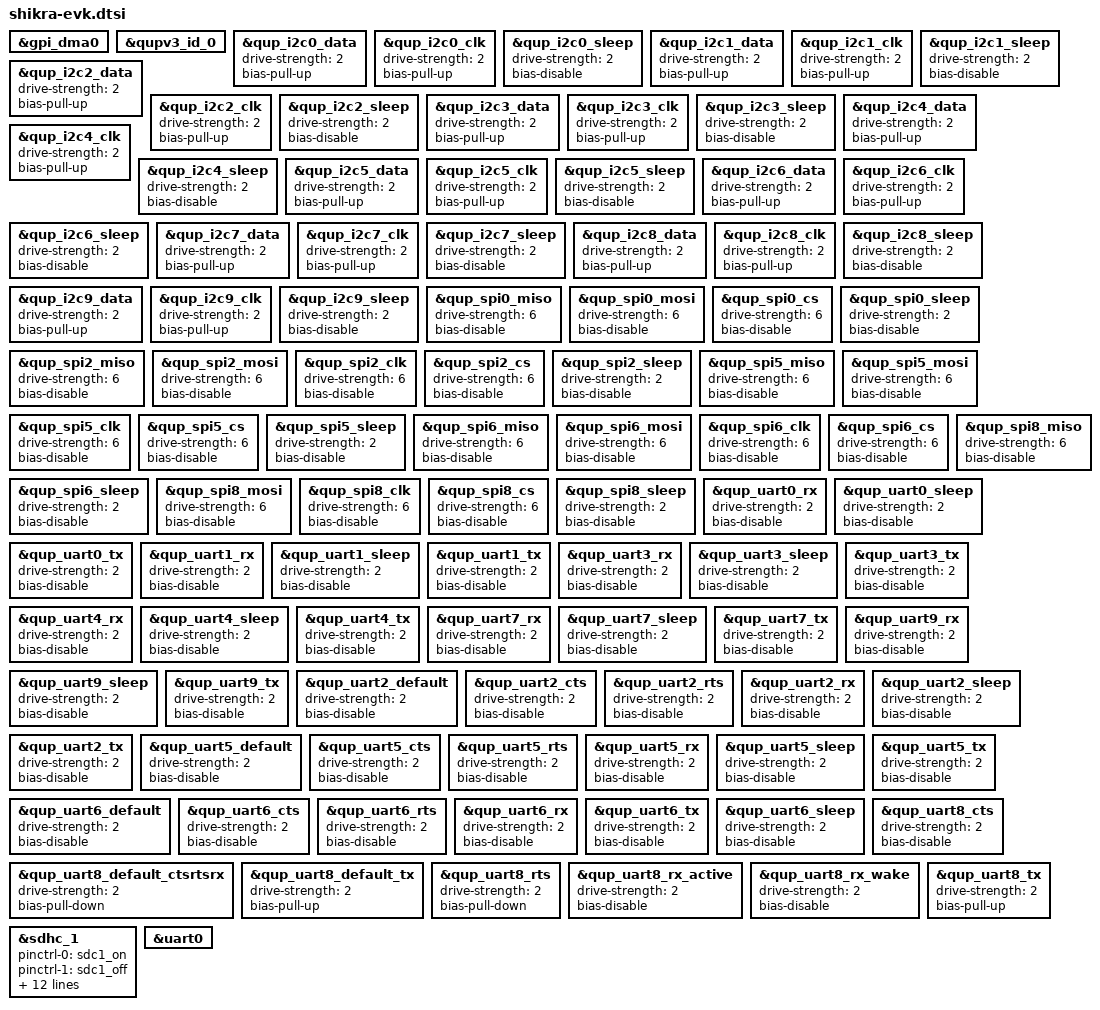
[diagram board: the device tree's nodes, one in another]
// SPDX-License-Identifier: BSD-3-Clause
/*
 * Copyright (c) Qualcomm Technologies, Inc. and/or its subsidiaries.
 */

&gpi_dma0 {
	status = "okay";
};

&qupv3_id_0 {
	status = "okay";
};

&qup_i2c0_data {
	drive-strength = <2>;
	bias-pull-up;
};

&qup_i2c0_clk {
	drive-strength = <2>;
	bias-pull-up;
};

&qup_i2c0_sleep {
	drive-strength = <2>;
	bias-disable;
};

&qup_i2c1_data {
	drive-strength = <2>;
	bias-pull-up;
};

&qup_i2c1_clk {
	drive-strength = <2>;
	bias-pull-up;
};

&qup_i2c1_sleep {
	drive-strength = <2>;
	bias-disable;
};

&qup_i2c2_data {
	drive-strength = <2>;
	bias-pull-up;
};

&qup_i2c2_clk {
	drive-strength = <2>;
	bias-pull-up;
};

&qup_i2c2_sleep {
	drive-strength = <2>;
	bias-disable;
};

&qup_i2c3_data {
	drive-strength = <2>;
	bias-pull-up;
};

&qup_i2c3_clk {
	drive-strength = <2>;
	bias-pull-up;
};

&qup_i2c3_sleep {
	drive-strength = <2>;
	bias-disable;
};

&qup_i2c4_data {
	drive-strength = <2>;
	bias-pull-up;
};

&qup_i2c4_clk {
	drive-strength = <2>;
	bias-pull-up;
};

&qup_i2c4_sleep {
	drive-strength = <2>;
	bias-disable;
};

&qup_i2c5_data {
	drive-strength = <2>;
	bias-pull-up;
};

&qup_i2c5_clk {
	drive-strength = <2>;
	bias-pull-up;
};

&qup_i2c5_sleep {
	drive-strength = <2>;
	bias-disable;
};

&qup_i2c6_data {
	drive-strength = <2>;
	bias-pull-up;
};

&qup_i2c6_clk {
	drive-strength = <2>;
	bias-pull-up;
};

&qup_i2c6_sleep {
	drive-strength = <2>;
	bias-disable;
};

&qup_i2c7_data {
	drive-strength = <2>;
	bias-pull-up;
};

&qup_i2c7_clk {
	drive-strength = <2>;
	bias-pull-up;
};

&qup_i2c7_sleep {
	drive-strength = <2>;
	bias-disable;
};

&qup_i2c8_data {
	drive-strength = <2>;
	bias-pull-up;
};

&qup_i2c8_clk {
	drive-strength = <2>;
	bias-pull-up;
};

&qup_i2c8_sleep {
	drive-strength = <2>;
	bias-disable;
};

&qup_i2c9_data {
	drive-strength = <2>;
	bias-pull-up;
};

&qup_i2c9_clk {
	drive-strength = <2>;
	bias-pull-up;
};

&qup_i2c9_sleep {
	drive-strength = <2>;
	bias-disable;
};

&qup_spi0_miso {
	drive-strength = <6>;
	bias-disable;
};

&qup_spi0_mosi {
	drive-strength = <6>;
	bias-disable;
};

&qup_spi0_cs {
	drive-strength = <6>;
	bias-disable;
};

&qup_spi0_sleep {
	drive-strength = <2>;
	bias-disable;
};

&qup_spi2_miso {
	drive-strength = <6>;
	bias-disable;
};

&qup_spi2_mosi {
	drive-strength = <6>;
	bias-disable;
};

&qup_spi2_clk {
	drive-strength = <6>;
	bias-disable;
};

&qup_spi2_cs {
	drive-strength = <6>;
	bias-disable;
};

&qup_spi2_sleep {
	drive-strength = <2>;
	bias-disable;
};

&qup_spi5_miso {
	drive-strength = <6>;
	bias-disable;
};

&qup_spi5_mosi {
	drive-strength = <6>;
	bias-disable;
};

&qup_spi5_clk {
	drive-strength = <6>;
	bias-disable;
};

&qup_spi5_cs {
	drive-strength = <6>;
	bias-disable;
};

&qup_spi5_sleep {
	drive-strength = <2>;
	bias-disable;
};

&qup_spi6_miso {
	drive-strength = <6>;
	bias-disable;
};

&qup_spi6_mosi {
	drive-strength = <6>;
	bias-disable;
};

&qup_spi6_clk {
	drive-strength = <6>;
	bias-disable;
};

&qup_spi6_cs {
	drive-strength = <6>;
	bias-disable;
};

&qup_spi6_sleep {
	drive-strength = <2>;
	bias-disable;
};

&qup_spi8_miso {
	drive-strength = <6>;
	bias-disable;
};

&qup_spi8_mosi {
	drive-strength = <6>;
	bias-disable;
};

&qup_spi8_clk {
	drive-strength = <6>;
	bias-disable;
};

&qup_spi8_cs {
	drive-strength = <6>;
	bias-disable;
};

&qup_spi8_sleep {
	drive-strength = <2>;
	bias-disable;
};

&qup_uart0_rx {
	drive-strength = <2>;
	bias-disable;
};

&qup_uart0_sleep {
	drive-strength = <2>;
	bias-disable;
};

&qup_uart0_tx {
	drive-strength = <2>;
	bias-disable;
};

&qup_uart1_rx {
	drive-strength = <2>;
	bias-disable;
};

&qup_uart1_sleep {
	drive-strength = <2>;
	bias-disable;
};

&qup_uart1_tx {
	drive-strength = <2>;
	bias-disable;
};

&qup_uart3_rx {
	drive-strength = <2>;
	bias-disable;
};

&qup_uart3_sleep {
	drive-strength = <2>;
	bias-disable;
};

&qup_uart3_tx {
	drive-strength = <2>;
	bias-disable;
};

&qup_uart4_rx {
	drive-strength = <2>;
	bias-disable;
};

&qup_uart4_sleep {
	drive-strength = <2>;
	bias-disable;
};

&qup_uart4_tx {
	drive-strength = <2>;
	bias-disable;
};

&qup_uart7_rx {
	drive-strength = <2>;
	bias-disable;
};

&qup_uart7_sleep {
	drive-strength = <2>;
	bias-disable;
};

&qup_uart7_tx {
	drive-strength = <2>;
	bias-disable;
};

&qup_uart9_rx {
	drive-strength = <2>;
	bias-disable;
};

&qup_uart9_sleep {
	drive-strength = <2>;
	bias-disable;
};

&qup_uart9_tx {
	drive-strength = <2>;
	bias-disable;
};

&qup_uart2_default {
	drive-strength = <2>;
	bias-disable;
};

&qup_uart2_cts {
	drive-strength = <2>;
	bias-disable;
};

&qup_uart2_rts {
	drive-strength = <2>;
	bias-disable;
};

&qup_uart2_rx {
	drive-strength = <2>;
	bias-disable;
};

&qup_uart2_sleep {
	drive-strength = <2>;
	bias-disable;
};

&qup_uart2_tx {
	drive-strength = <2>;
	bias-disable;
};

&qup_uart5_default {
	drive-strength = <2>;
	bias-disable;
};

&qup_uart5_cts {
	drive-strength = <2>;
	bias-disable;
};

&qup_uart5_rts {
	drive-strength = <2>;
	bias-disable;
};

&qup_uart5_rx {
	drive-strength = <2>;
	bias-disable;
};

&qup_uart5_sleep {
	drive-strength = <2>;
	bias-disable;
};

&qup_uart5_tx {
	drive-strength = <2>;
	bias-disable;
};

&qup_uart6_default {
	drive-strength = <2>;
	bias-disable;
};

&qup_uart6_cts {
	drive-strength = <2>;
	bias-disable;
};

&qup_uart6_rts {
	drive-strength = <2>;
	bias-disable;
};

&qup_uart6_rx {
	drive-strength = <2>;
	bias-disable;
};

&qup_uart6_tx {
	drive-strength = <2>;
	bias-disable;
};

&qup_uart6_sleep {
	drive-strength = <2>;
	bias-disable;
};

&qup_uart8_cts {
	drive-strength = <2>;
	bias-disable;
	};

&qup_uart8_default_ctsrtsrx {
	drive-strength = <2>;
	bias-pull-down;
	};

&qup_uart8_default_tx {
	drive-strength = <2>;
	bias-pull-up;
	};

&qup_uart8_rts {
	drive-strength = <2>;
	bias-pull-down;
	};

&qup_uart8_rx_active {
	drive-strength = <2>;
	bias-disable;
	};

&qup_uart8_rx_wake {
	drive-strength = <2>;
	bias-disable;
	};

&qup_uart8_tx {
	drive-strength = <2>;
	bias-pull-up;
	};

&sdhc_1 {
	pinctrl-0 = <&sdc1_on>;
	pinctrl-1 = <&sdc1_off>;
	pinctrl-names = "default", "sleep";

	vdd-supply = <&L20A>;
	qcom,vdd-voltage-level = <2952000 2952000>;
	qcom,vdd-current-level = <0 570340>;

	vdd-io-supply = <&L14A>;
	qcom,vdd-io-always-on;
	qcom,vdd-io-lpm-sup;
	qcom,vdd-io-voltage-level = <1800000 1800000>;
	qcom,vdd-io-current-level = <0 325560>;

	mmc-ddr-1_8v;
	mmc-hs200-1_8v;
	mmc-hs400-1_8v;
	mmc-hs400-enhanced-strobe;

	status = "okay";
};

&uart0 {
	status = "okay";
};
